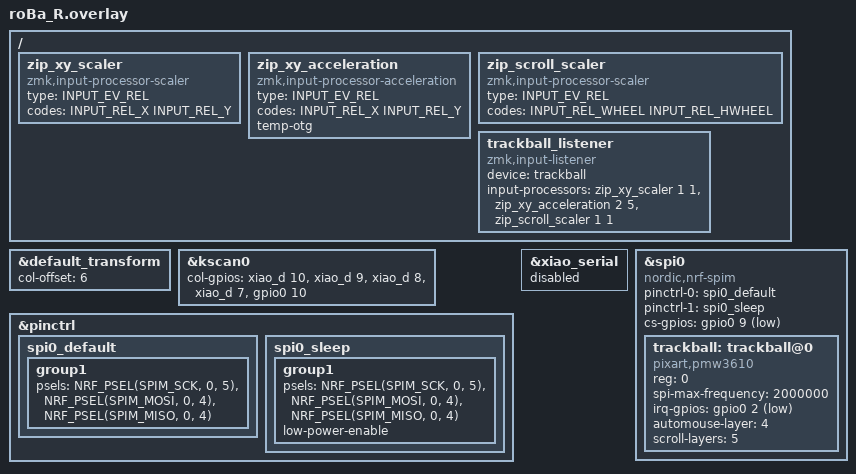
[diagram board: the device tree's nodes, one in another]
#include <dt-bindings/zmk/pointing.h>
#include <zephyr/dt-bindings/input/input-event-codes.h>
#include "roBa.dtsi"

&default_transform {
    col-offset = <6>;
};

&kscan0 {
    col-gpios
        = <&xiao_d 10 GPIO_ACTIVE_HIGH>
        , <&xiao_d 9 GPIO_ACTIVE_HIGH> 
        , <&xiao_d 8 GPIO_ACTIVE_HIGH> 
        , <&xiao_d 7 GPIO_ACTIVE_HIGH> 
        , <&gpio0 10 GPIO_ACTIVE_HIGH>
        ;
};

/ {
    /* ベース速度：等倍 */
    zip_xy_scaler: zip_xy_scaler {
        compatible = "zmk,input-processor-scaler";
        #input-processor-cells = <2>;
        type = <INPUT_EV_REL>;
        codes = <INPUT_REL_X INPUT_REL_Y>;
    };

    /* 加速設定：低速時は鈍感に、高速時は加速 */
    zip_xy_acceleration: zip_xy_acceleration {
        compatible = "zmk,input-processor-acceleration";
        #input-processor-cells = <2>;
        type = <INPUT_EV_REL>;
        codes = <INPUT_REL_X INPUT_REL_Y>;
        temp-otg;
    };

    zip_scroll_scaler: zip_scroll_scaler {
        compatible = "zmk,input-processor-scaler";
        #input-processor-cells = <2>;
        type = <INPUT_EV_REL>;
        codes = <INPUT_REL_WHEEL INPUT_REL_HWHEEL>;
    };

    trackball_listener {
        compatible = "zmk,input-listener";
        device = <&trackball>;
        /* スケーラーの後に加速を適用します */
        input-processors = 
            <&zip_xy_scaler 1 1>, 
            <&zip_xy_acceleration 2 5>, 
            <&zip_scroll_scaler 1 1>;
    };
};

&pinctrl {
    spi0_default: spi0_default {
        group1 {
            psels = <NRF_PSEL(SPIM_SCK, 0, 5)>,
                <NRF_PSEL(SPIM_MOSI, 0, 4)>,
                <NRF_PSEL(SPIM_MISO, 0, 4)>;
        };
    };

    spi0_sleep: spi0_sleep {
        group1 {
            psels = <NRF_PSEL(SPIM_SCK, 0, 5)>,
                <NRF_PSEL(SPIM_MOSI, 0, 4)>,
                <NRF_PSEL(SPIM_MISO, 0, 4)>;
            low-power-enable;
        };
    };
};

&xiao_serial { status = "disabled"; };

&spi0 {
    status = "okay";
    compatible = "nordic,nrf-spim";
    pinctrl-0 = <&spi0_default>;
    pinctrl-1 = <&spi0_sleep>;
    pinctrl-names = "default", "sleep";
    cs-gpios = <&gpio0 9 GPIO_ACTIVE_LOW>;

    trackball: trackball@0 {
        status = "okay";
        compatible = "pixart,pmw3610";
        reg = <0>;
        spi-max-frequency = <2000000>;
        irq-gpios = <&gpio0 2 (GPIO_ACTIVE_LOW | GPIO_PULL_UP)>;
        automouse-layer = <4>;
        scroll-layers = <5>;
    };
};
